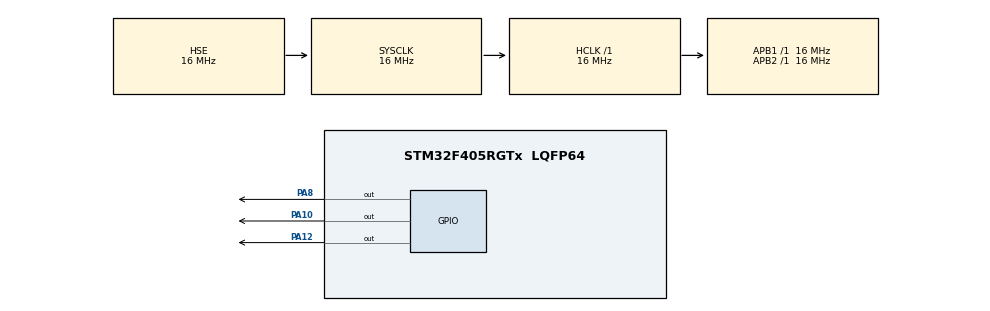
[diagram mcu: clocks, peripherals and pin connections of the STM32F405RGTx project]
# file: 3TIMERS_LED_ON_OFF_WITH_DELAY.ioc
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Mcu.Family=STM32F4
Mcu.Name=STM32F405RGTx
Mcu.Package=LQFP64
NVIC.PriorityGroup=NVIC_PRIORITYGROUP_4
NVIC.TIM3_IRQn=true\:0\:0\:false\:false\:true\:true\:true\:true
NVIC.TIM6_DAC_IRQn=true\:0\:0\:false\:false\:true\:true\:true\:true
NVIC.TIM7_IRQn=true\:0\:0\:false\:false\:true\:true\:true\:true
PA10.Signal=GPIO_Output
PA12.Signal=GPIO_Output
PA13.Mode=Serial_Wire
PA13.Signal=SYS_JTMS-SWDIO
PA14.Mode=Serial_Wire
PA14.Signal=SYS_JTCK-SWCLK
PA8.Signal=GPIO_Output
PH0-OSC_IN.Mode=HSE-External-Oscillator
PH0-OSC_IN.Signal=RCC_OSC_IN
PH1-OSC_OUT.Mode=HSE-External-Oscillator
PH1-OSC_OUT.Signal=RCC_OSC_OUT
ProjectManager.HeapSize=0x200
ProjectManager.StackSize=0x400
ProjectManager.TargetToolchain=MDK-ARM V5.32
RCC.AHBFreq_Value=16000000
RCC.APB1Freq_Value=16000000
RCC.APB2Freq_Value=16000000
RCC.CortexFreq_Value=16000000
RCC.HSE_VALUE=16000000
RCC.HSI_VALUE=16000000
RCC.LSE_VALUE=32768
RCC.PLLSourceVirtual=RCC_PLLSOURCE_HSE
RCC.SYSCLKFreq_VALUE=16000000
RCC.SYSCLKSource=RCC_SYSCLKSOURCE_HSE
RCC.VCOOutputFreq_Value=192000000
TIM3.Period=7999
TIM3.Prescaler=3999
TIM6.Period=7999
TIM6.Prescaler=999
TIM7.Period=7999
TIM7.Prescaler=1999
VP_TIM3_VS_ClockSourceINT.Mode=Internal
VP_TIM6_VS_ClockSourceINT.Mode=Enable_Timer
VP_TIM7_VS_ClockSourceINT.Mode=Enable_Timer
board=custom

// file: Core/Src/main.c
/* USER CODE BEGIN Header */
/**
  ******************************************************************************
  * @file           : main.c
  * @brief          : Main program body
  ******************************************************************************
  * @attention
  *
  * Copyright (c) 2023 STMicroelectronics.
  * All rights reserved.
  *
  * This software is licensed under terms that can be found in the LICENSE file
  * in the root directory of this software component.
  * If no LICENSE file comes with this software, it is provided AS-IS.
  *
  ******************************************************************************
  */
/* USER CODE END Header */
#include "main.h"

TIM_HandleTypeDef htim3;
TIM_HandleTypeDef htim6;
TIM_HandleTypeDef htim7;

void SystemClock_Config(void);
static void MX_GPIO_Init(void);
static void MX_TIM3_Init(void);
static void MX_TIM6_Init(void);
static void MX_TIM7_Init(void);

int main(void)
{

  /* MCU Configuration--------------------------------------------------------*/

  /* Reset of all peripherals, Initializes the Flash interface and the Systick. */
  HAL_Init();

  /* Configure the system clock */
  SystemClock_Config();

  /* Initialize all configured peripherals */
  MX_GPIO_Init();
  MX_TIM3_Init();
  MX_TIM6_Init();
  MX_TIM7_Init();
  /* USER CODE BEGIN 2 */
HAL_TIM_Base_Start_IT(&htim6);
HAL_TIM_Base_Start_IT(&htim7);
HAL_TIM_Base_Start_IT(&htim3);
  /* USER CODE END 2 */

  /* Infinite loop */
  while (1)
  {

  }
}

void HAL_TIM_PeriodElapsedCallback(TIM_HandleTypeDef *htim)
{
  if(htim->Instance==TIM6)
	{
    HAL_GPIO_TogglePin(GPIOA,GPIO_PIN_12);
	}
	if(htim->Instance==TIM7)
	{
		HAL_GPIO_TogglePin(GPIOA,GPIO_PIN_10);
	}
	if(htim->Instance==TIM3)
	{
		HAL_GPIO_TogglePin(GPIOA,GPIO_PIN_8);
	}
}

void SystemClock_Config(void)
{
  RCC_OscInitTypeDef RCC_OscInitStruct = {0};
  RCC_ClkInitTypeDef RCC_ClkInitStruct = {0};

  /** Configure the main internal regulator output voltage
  */
  __HAL_RCC_PWR_CLK_ENABLE();
  __HAL_PWR_VOLTAGESCALING_CONFIG(PWR_REGULATOR_VOLTAGE_SCALE1);

  /** Initializes the RCC Oscillators according to the specified parameters
  * in the RCC_OscInitTypeDef structure.
  */
  RCC_OscInitStruct.OscillatorType = RCC_OSCILLATORTYPE_HSE;
  RCC_OscInitStruct.HSEState = RCC_HSE_ON;
  RCC_OscInitStruct.PLL.PLLState = RCC_PLL_NONE;
  if (HAL_RCC_OscConfig(&RCC_OscInitStruct) != HAL_OK)
  {
    Error_Handler();
  }

  /** Initializes the CPU, AHB and APB buses clocks
  */
  RCC_ClkInitStruct.ClockType = RCC_CLOCKTYPE_HCLK|RCC_CLOCKTYPE_SYSCLK
                              |RCC_CLOCKTYPE_PCLK1|RCC_CLOCKTYPE_PCLK2;
  RCC_ClkInitStruct.SYSCLKSource = RCC_SYSCLKSOURCE_HSE;
  RCC_ClkInitStruct.AHBCLKDivider = RCC_SYSCLK_DIV1;
  RCC_ClkInitStruct.APB1CLKDivider = RCC_HCLK_DIV1;
  RCC_ClkInitStruct.APB2CLKDivider = RCC_HCLK_DIV1;

  if (HAL_RCC_ClockConfig(&RCC_ClkInitStruct, FLASH_LATENCY_0) != HAL_OK)
  {
    Error_Handler();
  }
}

static void MX_TIM3_Init(void)
{

  TIM_ClockConfigTypeDef sClockSourceConfig = {0};
  TIM_MasterConfigTypeDef sMasterConfig = {0};

  htim3.Instance = TIM3;
  htim3.Init.Prescaler = 3999;
  htim3.Init.CounterMode = TIM_COUNTERMODE_UP;
  htim3.Init.Period = 7999;
  htim3.Init.ClockDivision = TIM_CLOCKDIVISION_DIV1;
  htim3.Init.AutoReloadPreload = TIM_AUTORELOAD_PRELOAD_DISABLE;
  if (HAL_TIM_Base_Init(&htim3) != HAL_OK)
  {
    Error_Handler();
  }
  sClockSourceConfig.ClockSource = TIM_CLOCKSOURCE_INTERNAL;
  if (HAL_TIM_ConfigClockSource(&htim3, &sClockSourceConfig) != HAL_OK)
  {
    Error_Handler();
  }
  sMasterConfig.MasterOutputTrigger = TIM_TRGO_RESET;
  sMasterConfig.MasterSlaveMode = TIM_MASTERSLAVEMODE_DISABLE;
  if (HAL_TIMEx_MasterConfigSynchronization(&htim3, &sMasterConfig) != HAL_OK)
  {
    Error_Handler();
  }

}

static void MX_TIM6_Init(void)
{

  TIM_MasterConfigTypeDef sMasterConfig = {0};

  htim6.Instance = TIM6;
  htim6.Init.Prescaler = 999;
  htim6.Init.CounterMode = TIM_COUNTERMODE_UP;
  htim6.Init.Period = 7999;
  htim6.Init.AutoReloadPreload = TIM_AUTORELOAD_PRELOAD_DISABLE;
  if (HAL_TIM_Base_Init(&htim6) != HAL_OK)
  {
    Error_Handler();
  }
  sMasterConfig.MasterOutputTrigger = TIM_TRGO_RESET;
  sMasterConfig.MasterSlaveMode = TIM_MASTERSLAVEMODE_DISABLE;
  if (HAL_TIMEx_MasterConfigSynchronization(&htim6, &sMasterConfig) != HAL_OK)
  {
    Error_Handler();
  }

}

static void MX_TIM7_Init(void)
{

  TIM_MasterConfigTypeDef sMasterConfig = {0};

  htim7.Instance = TIM7;
  htim7.Init.Prescaler = 1999;
  htim7.Init.CounterMode = TIM_COUNTERMODE_UP;
  htim7.Init.Period = 7999;
  htim7.Init.AutoReloadPreload = TIM_AUTORELOAD_PRELOAD_DISABLE;
  if (HAL_TIM_Base_Init(&htim7) != HAL_OK)
  {
    Error_Handler();
  }
  sMasterConfig.MasterOutputTrigger = TIM_TRGO_RESET;
  sMasterConfig.MasterSlaveMode = TIM_MASTERSLAVEMODE_DISABLE;
  if (HAL_TIMEx_MasterConfigSynchronization(&htim7, &sMasterConfig) != HAL_OK)
  {
    Error_Handler();
  }

}

static void MX_GPIO_Init(void)
{
  GPIO_InitTypeDef GPIO_InitStruct = {0};

  /* GPIO Ports Clock Enable */
  __HAL_RCC_GPIOH_CLK_ENABLE();
  __HAL_RCC_GPIOA_CLK_ENABLE();

  /*Configure GPIO pin Output Level */
  HAL_GPIO_WritePin(GPIOA, GPIO_PIN_8|GPIO_PIN_10|GPIO_PIN_12, GPIO_PIN_RESET);

  /*Configure GPIO pins : PA8 PA10 PA12 */
  GPIO_InitStruct.Pin = GPIO_PIN_8|GPIO_PIN_10|GPIO_PIN_12;
  GPIO_InitStruct.Mode = GPIO_MODE_OUTPUT_PP;
  GPIO_InitStruct.Pull = GPIO_NOPULL;
  GPIO_InitStruct.Speed = GPIO_SPEED_FREQ_LOW;
  HAL_GPIO_Init(GPIOA, &GPIO_InitStruct);

}

void Error_Handler(void)
{
  __disable_irq();
  while (1)
  {
  }
}
